# nrf54h20_engb_secure register map
Vendor: Nordic Semiconductor; Series: nRF54h; File version: 1
CPU: CM33 r0p4, little endian, MPU, no FPU, 3 interrupt priority bits, 480 interrupts, 8 SAU regions
Registers are 32-bit, read-write, reset 0x0 unless marked. A register's access mark holds for its fields unless they carry their own. Offsets are from the block's base; [hi:lo] are bit positions; lines under a group give offsets from that group; {n}, {i} and the like mark numbered series; 'fields as' and 'values as' point back to an identical list.

## ABB_NS — ABB peripheral 0
Base 0x5101C000
Same registers: ABB_S 0x5101C000 (alternate view of ABB_NS)
0x00 TASKS_GETABBSTATUS wo — Get ABB status
  [0] TASKS_GETABBSTATUS
    1=Trigger task
0x100 EVENTS_ABBSTATUSREADY — The ABB status is ready for read
  [0] EVENTS_ABBSTATUSREADY
    0=NotGenerated (Event not generated); 1=Generated (Event generated)
0x300 INTEN — Enable or disable interrupt
  [0] ABBSTATUSREADY — Enable or disable interrupt for event ABBSTATUSREADY
    0=Disabled; 1=Enabled
0x304 INTENSET — Enable interrupt
  [0] ABBSTATUSREADY — Write '1' to enable interrupt for event ABBSTATUSREADY
    on read: 0=Disabled (Read: Disabled); 1=Enabled (Read: Enabled) | on write: 1=Set (Enable)
0x308 INTENCLR — Disable interrupt
  [0] ABBSTATUSREADY — Write '1' to disable interrupt for event ABBSTATUSREADY
    on read: 0=Disabled (Read: Disabled); 1=Enabled (Read: Enabled) | on write: 1=Clear (Disable)
0x30C INTPEND ro — Pending interrupts
  [0] ABBSTATUSREADY — Read pending status of interrupt for event ABBSTATUSREADY
    on read: 0=NotPending (Read: Not pending); 1=Pending (Read: Pending)
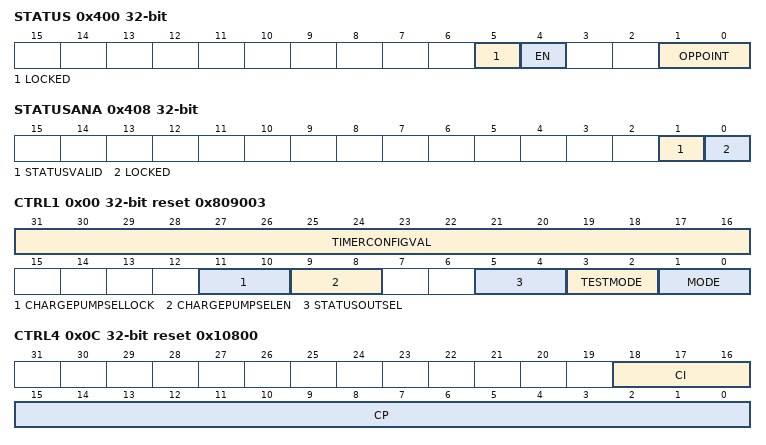
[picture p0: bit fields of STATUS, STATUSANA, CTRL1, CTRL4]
0x400 STATUS ro — ABB status
  [5] LOCKED — The ABB lock status.
    0=NotLocked; 1=Locked
  [4] EN — The ABB enable status.
    0=Disabled (ABB disabled); 1=Enabled (ABB enabled)
  [1:0] OPPOINT — The current ABB operating point
    0=OpPoint0V4 (Operating point 0.4V); 1=OpPoint0V5 (Operating point 0.5V); 2=OpPoint0V6 (Operating point 0.6V); 3=OpPoint0V8 (Operating point 0.8V)
0x404 STATUSABB ro — ABB macro status
  [31:0] STATUS — ABB macro status.
0x408 STATUSANA ro — Status of ABB macro output signals
  [1] STATUSVALID — Current value of the STATUS_VALID signal from the ABB macro
  [0] LOCKED — Current value of the LOCKED signal from the ABB macro
0x410 CONFIG group — Unspecified
  0x00 CTRL1 reset 0x809003 — ABB control 1
    [31:16] TIMERCONFIGVAL — Timer value that defines the length of one closed loop control cycle.
    [11:10] CHARGEPUMPSELLOCK — Charge pump stages enabled during lock-in
      0=NoSlice (No addition slice enabled); 1=Second slice enabled; 2=Third slice anabled; 3=BothSlices (Second and third slice enabled)
    [9:8] CHARGEPUMPSELEN — Additional charge pump slices and thereby define the drive strength of the body bias charge pump
      values as CHARGEPUMPSELLOCK
    [5:4] STATUSOUTSEL — Status output select
      0=Ringo count value and calibration done flag; 1=Locked status information, preliminary feature debugging only; 2=Filter status information, preliminary feature debugging only; 3=Ring oscillator information, preliminary feature debugging only
    [3:2] TESTMODE
      0=Normal operation; 1=TestPvtMon (PVT monitor test, Testclock switched to internal ripple counter); 2=CounterBist (Ripple counter bist mode)
    [1:0] MODE — ABB operation mode
      0=Auto; 1=Single PVT monitor readout (for test); 2=Open loop PWM charge pump drive (for test); 3=ZBB (Zero bias charge pump mode. VNW and VPW tied to VSS)
  0x0C CTRL4 reset 0x10800 — ABB control 4
    [18:16] CI — Integral path coefficient of the closed loop body bias controller.
    [15:0] CP — Proportional path coefficient of the closed loop body bias controller.
  0x10 VENDORCONFIG0 reset 0xB6000002
    [31:0] CONFIG — ABB vendor config register 0.
  0x14 VENDORCONFIG1 reset 0x120E7
    [20:0] CONFIG — ABB vendor config register 1.
0x440 TRIM group — Unspecified
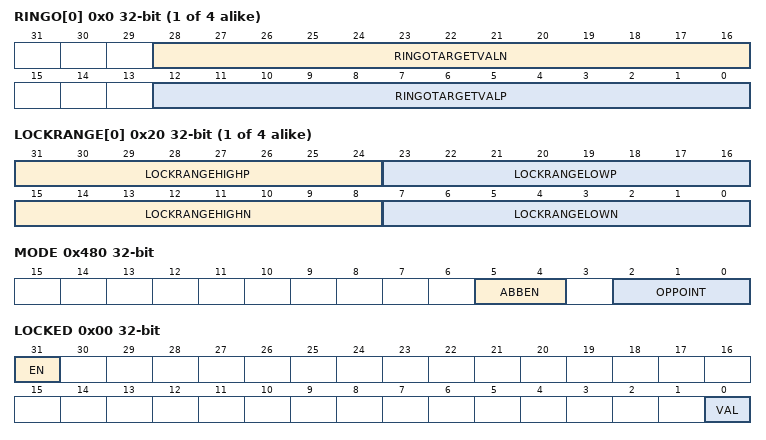
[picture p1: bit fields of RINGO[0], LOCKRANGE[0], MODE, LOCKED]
  {0x0+4j} RINGO[{j}] (j=0..3) — Description collection: RINGO trim values for operation points
    [28:16] RINGOTARGETVALN — Target performance for VNW biased devices.
    [12:0] RINGOTARGETVALP — Target performance for VPW biased devices.
  {0x20+4j} LOCKRANGE[{j}] (j=0..3) — Description collection: LOCKRANGE trim values for operation points
    [31:24] LOCKRANGEHIGHP — Lock range high boundary for VPW biased devices.
    [23:16] LOCKRANGELOWP — Lock range low boundary for VPW biased devices.
    [15:8] LOCKRANGEHIGHN — Lock range high boundary for VNW biased devices.
    [7:0] LOCKRANGELOWN — Lock range low boundary for VNW biased devices.
  {0x30+4j} PVTMONCYCLES[{j}] (j=0..3) — Description collection: PVTMONCYCLES trim values for operation points
    [3:0] VAL — These bits configure the internal monitor
0x480 MODE — ABB control
  [5:4] ABBEN — Enable ABB.
    0=Auto (The peripheral controls the ABB enable automatically based on request.); 1=Enable (Force enable ABB); 2=Disable (Force disable ABB)
  [2:0] OPPOINT — The ABB operating point.
    0=Auto (The peripheral controls the operating point automatically based on request from the master ABB controller.); 1=OpPoint0V4 (Force the operating point to 0.4V); 2=OpPoint0V5 (Force the operating point to 0.5V); 3=OpPoint0V6 (Force the operating point to 0.6V); 4=OpPoint0V8 (Force the operating point to 0.8V)
0x500 OVERRIDE group — Unspecified
  0x00 LOCKED — Override the LOCKED signal from the analog module
    [31] EN — Enable the override
      0=Disabled (Override is disabled); 1=Enabled (Override is enabled)
    [0] VAL — Current value of the signal
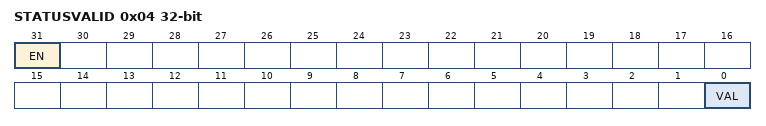
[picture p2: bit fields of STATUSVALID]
  0x04 STATUSVALID — Override the STATUS_VALID signal from the analog module
    fields as OVERRIDE.LOCKED
